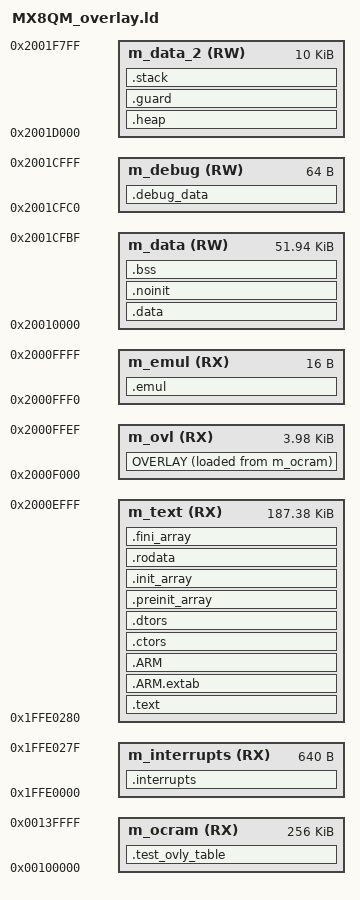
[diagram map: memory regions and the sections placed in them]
/*
** ###################################################################
**     Processors:          MX8
**
**     Compilers:           GNU C Compiler
**
**     Abstract:
**         CMSIS Peripheral Access Layer for MX8
**
**     Copyright 2019-2020 NXP
**
**     Redistribution and use in source and binary forms, with or without modification,
**     are permitted provided that the following conditions are met:
**
**     o Redistributions of source code must retain the above copyright notice, this list
**       of conditions and the following disclaimer.
**
**     o Redistributions in binary form must reproduce the above copyright notice, this
**       list of conditions and the following disclaimer in the documentation and/or
**       other materials provided with the distribution.
**
**     o Neither the name of the copyright holder nor the names of its
**       contributors may be used to endorse or promote products derived from this
**       software without specific prior written permission.
**
**     THIS SOFTWARE IS PROVIDED BY THE COPYRIGHT HOLDERS AND CONTRIBUTORS "AS IS" AND
**     ANY EXPRESS OR IMPLIED WARRANTIES, INCLUDING, BUT NOT LIMITED TO, THE IMPLIED
**     WARRANTIES OF MERCHANTABILITY AND FITNESS FOR A PARTICULAR PURPOSE ARE
**     DISCLAIMED. IN NO EVENT SHALL THE COPYRIGHT HOLDER OR CONTRIBUTORS BE LIABLE FOR
**     ANY DIRECT, INDIRECT, INCIDENTAL, SPECIAL, EXEMPLARY, OR CONSEQUENTIAL DAMAGES
**     (INCLUDING, BUT NOT LIMITED TO, PROCUREMENT OF SUBSTITUTE GOODS OR SERVICES;
**     LOSS OF USE, DATA, OR PROFITS; OR BUSINESS INTERRUPTION) HOWEVER CAUSED AND ON
**     ANY THEORY OF LIABILITY, WHETHER IN CONTRACT, STRICT LIABILITY, OR TORT
**     (INCLUDING NEGLIGENCE OR OTHERWISE) ARISING IN ANY WAY OUT OF THE USE OF THIS
**     SOFTWARE, EVEN IF ADVISED OF THE POSSIBILITY OF SUCH DAMAGE.
**
**
** ###################################################################
*/

/* DO NOT EDIT - This file auto generated by overlay_ld.pl */

OUTPUT_FORMAT("elf32-littlearm", "elf32-littlearm", "elf32-littlearm")
OUTPUT_ARCH(arm)

/* Entry Point */
ENTRY(Reset_Handler)

HEAP_SIZE  = DEFINED(__heap_size__)  ? __heap_size__  : 0x1000;
STACK_SIZE = DEFINED(__stack_size__) ? __stack_size__ : 0x1000;
EMUL_SIZE = DEFINED(__emul_size__) ? __emul_size__ : 0x0010;
DEBUG_DATA_SIZE = DEFINED(__debug_data_size__) ? __debug_data_size__ : 0x0040;

OCRAM_ADDR = 0x100000;

/* GUARD_LOG2 defines the power-of-2 size of the MPU guard region
 * used for runtime detection of stack/heap overflow.  Default
 * value is 11 => guard region = 2^11 = 2K
 */
GUARD_LOG2 = DEFINED(__guard_log2__) ? __guard_log2__ : 11;
GUARD_SIZE = (1 << GUARD_LOG2);

/* Specify the memory areas */
MEMORY
{
  m_ocram				(RX)  : ORIGIN = 0x00100000, LENGTH = 0x00040000
  m_interrupts          (RX)  : ORIGIN = 0x1ffe0000, LENGTH = 0x00000280
  m_text                (RX)  : ORIGIN = 0x1ffe0280, LENGTH = 0x0002ED80
  m_ovl                 (RX)  : ORIGIN = 0x2000F000, LENGTH = 0x00000FF0
  m_emul                (RX)  : ORIGIN = 0x2000fff0, LENGTH = 0x00000010
  m_data                (RW)  : ORIGIN = 0x20010000, LENGTH = 0x0000cfc0
  m_debug               (RW)  : ORIGIN = 0x2001cfc0, LENGTH = 0x00000040
  m_data_2              (RW)  : ORIGIN = 0x2001d000, LENGTH = 0x00002800
}

/* Define output sections */
SECTIONS
{ 
  /* The startup code goes first into internal flash */
  .interrupts : 
  {
    . = ALIGN(0x80);
    __VECTOR_TABLE = .;
    KEEP(*(.isr_vector))     /* Startup code */
    . = ALIGN(8);
  } > m_interrupts

  __VECTOR_RAM = __VECTOR_TABLE;
  __RAM_VECTOR_TABLE_SIZE_BYTES = 0x0;

  OVERLAY : NOCROSSREFS
   {
     .test0  { */test_dsc.o(.text*) */test_dsc.o(.rodata*) }
     .test1  { */test_pll.o(.text*) */test_pll.o(.rodata*) }
     .test2  { */test_snvs.o(.text*) */test_snvs.o(.rodata*) }
     .test3  { */test_pmic.o(.text*) */test_pmic.o(.rodata*) }
     .test4  { */test_dblogic.o(.text*) */test_dblogic.o(.rodata*) }
     .test5  { */test_db.o(.text*) */test_db.o(.rodata*) }
     .test6  { */test_drc.o(.text*) */test_drc.o(.rodata*) }
     .test7  { */test_lsio.o(.text*) */test_lsio.o(.rodata*) }
     .test8  { */test_dma.o(.text*) */test_dma.o(.rodata*) }
     .test9  { */test_conn.o(.text*) */test_conn.o(.rodata*) }
     .test10  { */test_cci.o(.text*) */test_cci.o(.rodata*) }
     .test11  { */test_ap.o(.text*) */test_ap.o(.rodata*) }
     .test12  { */test_audio.o(.text*) */test_audio.o(.rodata*) }
     .test13  { */test_dc.o(.text*) */test_dc.o(.rodata*) }
     .test14  { */test_mipi.o(.text*) */test_mipi.o(.rodata*) }
     .test15  { */test_lvds.o(.text*) */test_lvds.o(.rodata*) }
     .test16  { */test_dc_lvds.o(.text*) */test_dc_lvds.o(.rodata*) }
     .test17  { */test_hdmi.o(.text*) */test_hdmi.o(.rodata*) }
     .test18  { */test_img.o(.text*) */test_img.o(.rodata*) }
     .test19  { */test_csi.o(.text*) */test_csi.o(.rodata*) }
     .test20  { */test_hdmi_rx.o(.text*) */test_hdmi_rx.o(.rodata*) }
     .test21  { */test_gpu.o(.text*) */test_gpu.o(.rodata*) }
     .test22  { */test_vpu.o(.text*) */test_vpu.o(.rodata*) }
     .test23  { */test_hsio.o(.text*) */test_hsio.o(.rodata*) }
     .test24  { */test_mcu.o(.text*) */test_mcu.o(.rodata*) }
     .test25  { */test_lcdif.o(.text*) */test_lcdif.o(.rodata*) }
     .test26  { */test_isi.o(.text*) */test_isi.o(.rodata*) }
     .test27  { */test_pd.o(.text*) */test_pd.o(.rodata*) }
     .test28  { */test_pm.o(.text*) */test_pm.o(.rodata*) }
     .test29  { */test_timer.o(.text*) */test_timer.o(.rodata*) }
     .test30  { */test_rm.o(.text*) */test_rm.o(.rodata*) }
     .test31  { */test_misc.o(.text*) */test_misc.o(.rodata*) }
     .test32  { */test_pad.o(.text*) */test_pad.o(.rodata*) }
     .test33  { */test_rm2.o(.text*) */test_rm2.o(.rodata*) }
     .test34  { */test_seco.o(.text*) */test_seco.o(.rodata*) }
     .test35  { */test_hexdump.o(.text*) */test_hexdump.o(.rodata*) }
     .test36  { */test_ddr.o(.text*) */test_ddr.o(.rodata*) }
     .test37  { */test_audio_pll.o(.text*) */test_audio_pll.o(.rodata*) }
     .test38  { */test_temp.o(.text*) */test_temp.o(.rodata*) }
     .test39  { */test_uboot.o(.text*) */test_uboot.o(.rodata*) }
     .test40  { */test_xrdc.o(.text*) */test_xrdc.o(.rodata*) }
     .test41  { */test_dump.o(.text*) */test_dump.o(.rodata*) }
     .test42  { */test_rpc.o(.text*) */test_rpc.o(.rodata*) }
   } > m_ovl AT> m_ocram

  .test_ovly_table :
  {
    . = ALIGN(4);
    __ovly_table = .; 
        LONG(0x34982933); LONG(0); LONG(42);
        LONG(ABSOLUTE(ADDR(.test0))); LONG(SIZEOF(.test0)); LONG(LOADADDR(.test0));
        LONG(ABSOLUTE(ADDR(.test1))); LONG(SIZEOF(.test1)); LONG(LOADADDR(.test1));
        LONG(ABSOLUTE(ADDR(.test2))); LONG(SIZEOF(.test2)); LONG(LOADADDR(.test2));
        LONG(ABSOLUTE(ADDR(.test3))); LONG(SIZEOF(.test3)); LONG(LOADADDR(.test3));
        LONG(ABSOLUTE(ADDR(.test4))); LONG(SIZEOF(.test4)); LONG(LOADADDR(.test4));
        LONG(ABSOLUTE(ADDR(.test5))); LONG(SIZEOF(.test5)); LONG(LOADADDR(.test5));
        LONG(ABSOLUTE(ADDR(.test6))); LONG(SIZEOF(.test6)); LONG(LOADADDR(.test6));
        LONG(ABSOLUTE(ADDR(.test7))); LONG(SIZEOF(.test7)); LONG(LOADADDR(.test7));
        LONG(ABSOLUTE(ADDR(.test8))); LONG(SIZEOF(.test8)); LONG(LOADADDR(.test8));
        LONG(ABSOLUTE(ADDR(.test9))); LONG(SIZEOF(.test9)); LONG(LOADADDR(.test9));
        LONG(ABSOLUTE(ADDR(.test10))); LONG(SIZEOF(.test10)); LONG(LOADADDR(.test10));
        LONG(ABSOLUTE(ADDR(.test11))); LONG(SIZEOF(.test11)); LONG(LOADADDR(.test11));
        LONG(ABSOLUTE(ADDR(.test12))); LONG(SIZEOF(.test12)); LONG(LOADADDR(.test12));
        LONG(ABSOLUTE(ADDR(.test13))); LONG(SIZEOF(.test13)); LONG(LOADADDR(.test13));
        LONG(ABSOLUTE(ADDR(.test14))); LONG(SIZEOF(.test14)); LONG(LOADADDR(.test14));
        LONG(ABSOLUTE(ADDR(.test15))); LONG(SIZEOF(.test15)); LONG(LOADADDR(.test15));
        LONG(ABSOLUTE(ADDR(.test16))); LONG(SIZEOF(.test16)); LONG(LOADADDR(.test16));
        LONG(ABSOLUTE(ADDR(.test17))); LONG(SIZEOF(.test17)); LONG(LOADADDR(.test17));
        LONG(ABSOLUTE(ADDR(.test18))); LONG(SIZEOF(.test18)); LONG(LOADADDR(.test18));
        LONG(ABSOLUTE(ADDR(.test19))); LONG(SIZEOF(.test19)); LONG(LOADADDR(.test19));
        LONG(ABSOLUTE(ADDR(.test20))); LONG(SIZEOF(.test20)); LONG(LOADADDR(.test20));
        LONG(ABSOLUTE(ADDR(.test21))); LONG(SIZEOF(.test21)); LONG(LOADADDR(.test21));
        LONG(ABSOLUTE(ADDR(.test22))); LONG(SIZEOF(.test22)); LONG(LOADADDR(.test22));
        LONG(ABSOLUTE(ADDR(.test23))); LONG(SIZEOF(.test23)); LONG(LOADADDR(.test23));
        LONG(ABSOLUTE(ADDR(.test24))); LONG(SIZEOF(.test24)); LONG(LOADADDR(.test24));
        LONG(ABSOLUTE(ADDR(.test25))); LONG(SIZEOF(.test25)); LONG(LOADADDR(.test25));
        LONG(ABSOLUTE(ADDR(.test26))); LONG(SIZEOF(.test26)); LONG(LOADADDR(.test26));
        LONG(ABSOLUTE(ADDR(.test27))); LONG(SIZEOF(.test27)); LONG(LOADADDR(.test27));
        LONG(ABSOLUTE(ADDR(.test28))); LONG(SIZEOF(.test28)); LONG(LOADADDR(.test28));
        LONG(ABSOLUTE(ADDR(.test29))); LONG(SIZEOF(.test29)); LONG(LOADADDR(.test29));
        LONG(ABSOLUTE(ADDR(.test30))); LONG(SIZEOF(.test30)); LONG(LOADADDR(.test30));
        LONG(ABSOLUTE(ADDR(.test31))); LONG(SIZEOF(.test31)); LONG(LOADADDR(.test31));
        LONG(ABSOLUTE(ADDR(.test32))); LONG(SIZEOF(.test32)); LONG(LOADADDR(.test32));
        LONG(ABSOLUTE(ADDR(.test33))); LONG(SIZEOF(.test33)); LONG(LOADADDR(.test33));
        LONG(ABSOLUTE(ADDR(.test34))); LONG(SIZEOF(.test34)); LONG(LOADADDR(.test34));
        LONG(ABSOLUTE(ADDR(.test35))); LONG(SIZEOF(.test35)); LONG(LOADADDR(.test35));
        LONG(ABSOLUTE(ADDR(.test36))); LONG(SIZEOF(.test36)); LONG(LOADADDR(.test36));
        LONG(ABSOLUTE(ADDR(.test37))); LONG(SIZEOF(.test37)); LONG(LOADADDR(.test37));
        LONG(ABSOLUTE(ADDR(.test38))); LONG(SIZEOF(.test38)); LONG(LOADADDR(.test38));
        LONG(ABSOLUTE(ADDR(.test39))); LONG(SIZEOF(.test39)); LONG(LOADADDR(.test39));
        LONG(ABSOLUTE(ADDR(.test40))); LONG(SIZEOF(.test40)); LONG(LOADADDR(.test40));
        LONG(ABSOLUTE(ADDR(.test41))); LONG(SIZEOF(.test41)); LONG(LOADADDR(.test41));
        LONG(ABSOLUTE(ADDR(.test42))); LONG(SIZEOF(.test42)); LONG(LOADADDR(.test42));
        LONG(0); LONG(0); LONG(0);
  } > m_ocram

  /* The program code and other data goes into TCM */
  .text : 
  {
    . = ALIGN(8);
    *(.text)                 /* .text sections (code) */
    *(.text*)                /* .text* sections (code) */
    *(.glue_7)               /* glue arm to thumb code */
    *(.glue_7t)              /* glue thumb to arm code */
    *(.eh_frame)
    KEEP (*(.init))
    KEEP (*(.fini))
    . = ALIGN(4);
  } > m_text

  .ARM.extab : 
  {
    *(.ARM.extab* .gnu.linkonce.armextab.*)
  } > m_text

  .ARM : 
  {
    __exidx_start = .;
    *(.ARM.exidx*)
    __exidx_end = .;
  } > m_text

 .ctors : 
  {
    __CTOR_LIST__ = .;
    /* gcc uses crtbegin.o to find the start of
       the constructors, so we make sure it is
       first.  Because this is a wildcard, it
       doesn't matter if the user does not
       actually link against crtbegin.o; the
       linker won't look for a file to match a
       wildcard.  The wildcard also means that it
       doesn't matter which directory crtbegin.o
       is in.  */
    KEEP (*crtbegin.o(.ctors))
    KEEP (*crtbegin?.o(.ctors))
    /* We don't want to include the .ctor section from
       from the crtend.o file until after the sorted ctors.
       The .ctor section from the crtend file contains the
       end of ctors marker and it must be last */
    KEEP (*(EXCLUDE_FILE(*crtend?.o *crtend.o) .ctors))
    KEEP (*(SORT(.ctors.*)))
    KEEP (*(.ctors))
    __CTOR_END__ = .;
  } > m_text

  .dtors : 
  {
    __DTOR_LIST__ = .;
    KEEP (*crtbegin.o(.dtors))
    KEEP (*crtbegin?.o(.dtors))
    KEEP (*(EXCLUDE_FILE(*crtend?.o *crtend.o) .dtors))
    KEEP (*(SORT(.dtors.*)))
    KEEP (*(.dtors))
    __DTOR_END__ = .;
  } > m_text

  .preinit_array : 
  {
    PROVIDE_HIDDEN (__preinit_array_start = .);
    KEEP (*(.preinit_array*))
    PROVIDE_HIDDEN (__preinit_array_end = .);
  } > m_text

  .init_array : 
  {
    PROVIDE_HIDDEN (__init_array_start = .);
    KEEP (*(SORT(.init_array.*)))
    KEEP (*(.init_array*))
    PROVIDE_HIDDEN (__init_array_end = .);
  } > m_text

  /* Constants/strings linked to end of image and are allowed to spill over 
     from TCML to TCMU without access penalty (DCODE bus access).  Alignment
     faults must be enabled to ensure an access across the boundary is detected
     not occur */
  .rodata : 
  {
    *(.rodata)               /* .rodata sections (constants, strings, etc.) */
    *(.rodata*)              /* .rodata* sections (constants, strings, etc.) */
  } > m_text

  .fini_array : 
  {
    PROVIDE_HIDDEN (__fini_array_start = .);
    KEEP (*(SORT(.fini_array.*)))
    KEEP (*(.fini_array*))
    PROVIDE_HIDDEN (__fini_array_end = .);
    . = ALIGN(64);
  } > m_text

  __etext = .;    /* define a global symbol at end of code */
  __DATA_ROM = .; /* Symbol is used by startup for data initialization */

  .emul :
  {
    __EMUL = .;
    . += EMUL_SIZE;
  } > m_emul

  /* Ensure .data 64-byte aligned for optimized copy */
  .data : AT( LOADADDR(.fini_array) + SIZEOF(.fini_array))
  {
    . = ALIGN(64);
    __DATA_RAM = .;
    __data_start__ = .;      /* create a global symbol at data start */
    *(.data)                 /* .data sections */
    *(.data*)                /* .data* sections */
    KEEP(*(.jcr*))
    . = ALIGN(64);
    __data_end__ = .;        /* define a global symbol at data end */
  } > m_data

  copy_start = LOADADDR(.interrupts);
  copy_end = copy_start;
  copy_dest = copy_start;
  __DATA_END = __DATA_ROM + (__data_end__ - __data_start__);

  /* Uninitialized data section with NO zeroization 
   *
   * Note:  section attribute NOLOAD prevents the linker from allocating space in 
   *        the loadable image (i.e. section type marked NOBITS instead of PROGBITS)
   */
  .noinit (NOLOAD) :
  {
    . = ALIGN(64);
    __NoInitBase = .;
    *(.noinit)
    *(.noinit*)
    . = ALIGN(64);
    __NoInitEnd = .;
  } > m_data

  /* Uninitialized data section */
  .bss :
  {
    /* This is used by the startup in order to initialize the .bss section */
    . = ALIGN(64);
    __START_BSS = .;
    __bss_start__ = .;
    *(.bss)
    *(.bss*)
    *(COMMON)
    . = ALIGN(64);
    __bss_end__ = .;
    __END_BSS = .;
    __FREE_TCM_START = .;
  } > m_data

  .debug_data :
  {
    __FREE_TCM_END = .;
    __DEBUG_DATA = .;
    . += DEBUG_DATA_SIZE;
  } > m_debug

  .heap :
  {
    . = ALIGN(64);
    __end__ = .;
    PROVIDE(end = .);
    __HeapBase = .;
    . += HEAP_SIZE;
    __HeapLimit = .;
    . = ALIGN(64);
  } > m_data_2

  .guard :
  {
    . = ALIGN(GUARD_SIZE);
    __GuardStart = .;
    . += GUARD_SIZE;
    __GuardLimit = .;
  } > m_data_2

  __GuardSizeMpuField = (GUARD_LOG2 - 1) << 1;

  .stack :
  {
    . = ALIGN(64);
    . += STACK_SIZE;
    . = ALIGN(64);
  } > m_data_2

  /* Initializes stack on the end of block */
  __StackTop   = ORIGIN(m_data_2) + LENGTH(m_data_2);
  __StackLimit = __StackTop - STACK_SIZE;
  PROVIDE(__stack = __StackTop);

  __FREE_TCM_BYTES = __FREE_TCM_END - __FREE_TCM_START;
  __FREE_TCM_WORDS = __FREE_TCM_BYTES >> 2;

  /DISCARD/ : { *(.interp) }
  .ARM.attributes 0 : { *(.ARM.attributes) }

  ASSERT(__StackLimit >= __GuardLimit, "region m_data_2 overflowed with stack and heap")
  ASSERT(__DATA_END < __EMUL, "region m_text overflowed with initialized data")
}

